# S6E1A1 register map
File version: 1.2
S6E1A1 Series
CPU: 
Registers are 32-bit, read-write, reset 0x0 unless marked. A register's access mark holds for its fields unless they carry their own. Offsets are from the block's base; lines under a group give offsets from that group; [hi:lo] are bit positions; {n}, {i} and the like mark numbered series; 'fields as' and 'values as' point back to an identical list; <NAME> marks a mode.

## Memory map
0x40000000 FLASH_IF blocks up to offset 0x5 — Flash Memory
0x40000200 UNIQUE_ID size 0x4
0x40010000 CLOCK size 0x1 — Clock Unit Registers
0x40011000 HWWDT size 0x4 — Hardware Watchdog Timer
0x40012000 SWWDT size 0x4 — Software Watchdog Timer
0x40015000 DTIM size 0x1C — Dual Timer
0x40020000 MFT0 blocks up to offset 0x104 — Multifunction Timer 0
0x40024000 MFT_PPG size 0x2 — PPG Configuration Registers
0x40025000 BT0 size 0x2 — Base Timer 0
0x40025040 BT1 size 0x2 — Base Timer 0
0x40025080 BT2 size 0x2 — Base Timer 0
0x400250C0 BT3 size 0x2 — Base Timer 0
0x40025100 BTIOSEL03 size 0x2 — Base Timer I/O Select
0x40025F00 SBSSR blocks up to offset 0xFE — Software-based Simultaneous Startup Register
0x40026000 QPRC0 size 0x2 — Quadrature Position/Revolution Counter 0
0x40026100 QPRC0_NF size 0x2 — Quadrature Position/Revolution Counter 0 Noise Filter
0x40027000 ADC0 size 0x2 — ADC0 Registers
0x4002E000 CRTRIM size 0x1 — CR Trimming Registers
0x40030000 EXTI size 0x4 — External Interrupt and NMI Control
0x40031000 INTREQ size 0x4 — Interrupts
0x40033000 GPIO size 0x40 — I/O Port Registers
0x40035000 LVD size 0x2 — Low-voltage Detection
0x40035100 DS size 0x1 — Low Power Consumption Mode Registers
0x40038000 MFS0 size 0x2 — Multi-function Serial Interface 0
0x40038100 MFS1 size 0x2 — Multi-function Serial Interface 0
0x40038300 MFS3 size 0x2 — Multi-function Serial Interface 0
0x40039000 CRC size 0x1 — CRC Registers
0x4003A000 WC size 0x3 — Watch Counter
0x4003B000 RTC size 0x13 — REAL-TIME CLOCK
0x4003C000 LSCRP size 0x1 — Low-speed CR Prescaler Register
0x4003C100 PCG size 0x4 — Peripheral Clock Gating Registers
0x40060000 DMAC size 0x4 — DMAC Registers
0xF0001000 MTB_DWT size 0x4 — Micro Trace Buffer Data Watchpoint and Trace Registers
0xF8000000 FASTIO size 0x100 — Fast GPIO Registers

## Interrupts
0 CSV (CLOCK)
1 SWDT (SWWDT)
2 LVD
3 WFG_DTIF (MFT0)
4 EXINT0_7 (EXTI)
6 DTIM_QDU (DTIM, QPRC0)
7 MFS0RX (MFS0)
8 MFS0TX (MFS0)
9 MFS1RX (MFS1)
10 MFS1TX (MFS1)
13 MFS3RX (MFS3)
14 MFS3TX (MFS3)
19 DMAC0 (DMAC)
20 DMAC1 (DMAC)
23 PPG (MFT_PPG)
24 OSC_PLL_WC_RTC (CLOCK, WC, RTC)
25 ADC0
28 FRTIM (MFT0)
29 INCAP (MFT0)
30 OUTCOMP (MFT0)
31 BTIM0_3_FLASH (FLASH_IF, BT{n} (n=0..3))

## FLASH_IF — Flash Memory
Base 0x40000000
0x04 FRWTR 8-bit reset 0x1 — Flash Read Wait Register
  [1:0] RWT — Read Wait Cycle
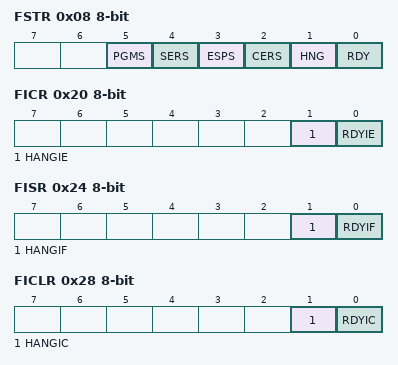
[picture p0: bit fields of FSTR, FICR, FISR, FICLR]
0x08 FSTR 8-bit ro — Flash Status Register
  [5] PGMS — Flash Program Status
  [4] SERS — Flash Sector Erase Status
  [3] ESPS — Flash Erase Suspend Status
  [2] CERS — Flash Chip Erase Status
  [1] HNG — Flash Hang Status
  [0] RDY — Flash Ready Status
0x10 FSYNDN 8-bit reset 0x1 — Flash Sync Down Register
  [3:0] SD — Sync Down
0x20 FICR 8-bit — Flash Interrupt Control Register
  [1] HANGIE — HANG Interrupt Enable
  [0] RDYIE — RDY Interrupt Enable
0x24 FISR 8-bit — Flash Interrupt Status Register
  [1] HANGIF — HANG Interrupt Flag
  [0] RDYIF — RDY Interrupt Flag
0x28 FICLR 8-bit wo — Flash Interrupt Clear Register
  [1] HANGIC — HANG Interrupt Clear
  [0] RDYIC — RDY Interrupt Clear
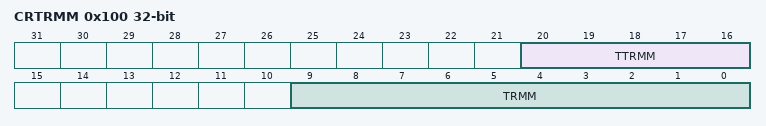
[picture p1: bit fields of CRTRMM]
0x100 CRTRMM ro — CR Trimming Data Mirror Register
  [20:16] TTRMM — CR Temperature Trimming Data Mirror Bit
  [9:0] TRMM — CR Trimming Data Mirror Bit

## UNIQUE_ID
Base 0x40000200
0x00 UIDR0 ro — Unique ID Register 0
  [31:4] UID — Unique ID 27 through Unique ID 0
0x04 UIDR1 ro — Unique ID Register 1
  [12:0] UID — Unique ID 40 through Unique ID 28

## HWWDT — Hardware Watchdog Timer
Base 0x40011000
0x00 WDG_LDR reset 0xFFFF — Hardware Watchdog Timer Load Register
0x04 WDG_VLR ro — Hardware Watchdog Timer Value Register
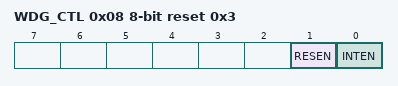
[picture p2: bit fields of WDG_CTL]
0x08 WDG_CTL 8-bit reset 0x3 — Hardware Watchdog Timer Control Register
  [1] RESEN — Hardware watchdog reset enable bit
  [0] INTEN — Hardware watchdog interrupt and counter enable bit
0x0C WDG_ICL 8-bit — Hardware Watchdog Timer Clear Register
0x10 WDG_RIS 8-bit ro — Hardware Watchdog Timer Interrupt Status Register
  [0] RIS — Hardware watchdog interrupt status bit
0xC00 WDG_LCK reset 0x1 — Hardware Watchdog Timer Lock Register
